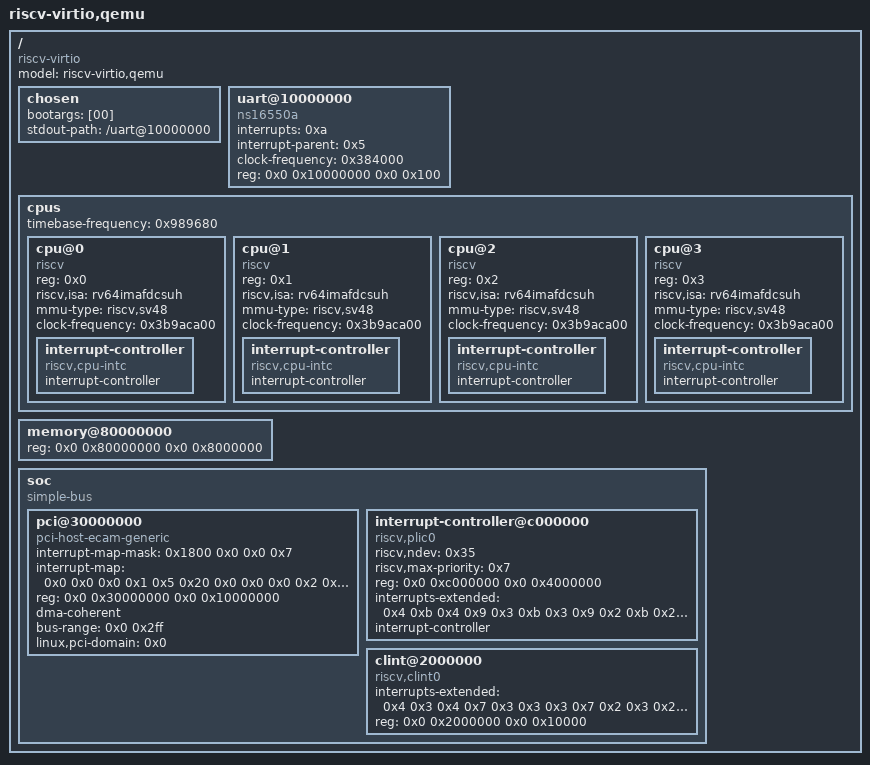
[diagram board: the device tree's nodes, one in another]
/dts-v1/;

/ {
	#address-cells = <0x2>;
	#size-cells = <0x2>;
	compatible = "riscv-virtio";
	model = "riscv-virtio,qemu";

	chosen {
		bootargs = [00];
		stdout-path = "/uart@10000000";
	};

	uart@10000000 {
		interrupts = <0xa>;
		interrupt-parent = <0x5>;
		clock-frequency = <0x384000>;
		reg = <0x0 0x10000000 0x0 0x100>;
		compatible = "ns16550a";
	};

	cpus {
		#address-cells = <0x1>;
		#size-cells = <0x0>;
		timebase-frequency = <0x989680>;

		cpu@0 {
			device_type = "cpu";
			reg = <0x0>;
			status = "okay";
			compatible = "riscv";
			riscv,isa = "rv64imafdcsuh";
			mmu-type = "riscv,sv48";
			clock-frequency = <0x3b9aca00>;

			interrupt-controller {
				#interrupt-cells = <0x1>;
				interrupt-controller;
				compatible = "riscv,cpu-intc";
				linux,phandle = <0x4>;
				phandle = <0x4>;
			};
		};

		cpu@1 {
			device_type = "cpu";
			reg = <0x1>;
			status = "okay";
			compatible = "riscv";
			riscv,isa = "rv64imafdcsuh";
			mmu-type = "riscv,sv48";
			clock-frequency = <0x3b9aca00>;

			interrupt-controller {
				#interrupt-cells = <0x1>;
				interrupt-controller;
				compatible = "riscv,cpu-intc";
				linux,phandle = <0x3>;
				phandle = <0x3>;
			};
		};

		cpu@2 {
			device_type = "cpu";
			reg = <0x2>;
			status = "okay";
			compatible = "riscv";
			riscv,isa = "rv64imafdcsuh";
			mmu-type = "riscv,sv48";
			clock-frequency = <0x3b9aca00>;

			interrupt-controller {
				#interrupt-cells = <0x1>;
				interrupt-controller;
				compatible = "riscv,cpu-intc";
				linux,phandle = <0x2>;
				phandle = <0x2>;
			};
		};

		cpu@3 {
			device_type = "cpu";
			reg = <0x3>;
			status = "okay";
			compatible = "riscv";
			riscv,isa = "rv64imafdcsuh";
			mmu-type = "riscv,sv48";
			clock-frequency = <0x3b9aca00>;

			interrupt-controller {
				#interrupt-cells = <0x1>;
				interrupt-controller;
				compatible = "riscv,cpu-intc";
				linux,phandle = <0x1>;
				phandle = <0x1>;
			};
		};
	};

	memory@80000000 {
		device_type = "memory";
		reg = <0x0 0x80000000 0x0 0x8000000>;
	};

	soc {
		#address-cells = <0x2>;
		#size-cells = <0x2>;
		compatible = "simple-bus";
		ranges;

		pci@30000000 {
			interrupt-map-mask = <0x1800 0x0 0x0 0x7>;
			interrupt-map = <0x0 0x0 0x0 0x1 0x5 0x20 0x0 0x0 0x0 0x2 0x5 0x21 0x0 0x0 0x0 0x3 0x5 0x22 0x0 0x0 0x0 0x4 0x5 0x23 0x800 0x0 0x0 0x1 0x5 0x21 0x800 0x0 0x0 0x2 0x5 0x22 0x800 0x0 0x0 0x3 0x5 0x23 0x800 0x0 0x0 0x4 0x5 0x20 0x1000 0x0 0x0 0x1 0x5 0x22 0x1000 0x0 0x0 0x2 0x5 0x23 0x1000 0x0 0x0 0x3 0x5 0x20 0x1000 0x0 0x0 0x4 0x5 0x21 0x1800 0x0 0x0 0x1 0x5 0x23 0x1800 0x0 0x0 0x2 0x5 0x20 0x1800 0x0 0x0 0x3 0x5 0x21 0x1800 0x0 0x0 0x4 0x5 0x22>;
			ranges = <0x1000000 0x0 0x0 0x0 0x3000000 0x0 0x10000 0x2000000 0x0 0x40000000 0x0 0x40000000 0x0 0x40000000>;
			reg = <0x0 0x30000000 0x0 0x10000000>;
			dma-coherent;
			bus-range = <0x0 0x2ff>;
			linux,pci-domain = <0x0>;
			device_type = "pci";
			compatible = "pci-host-ecam-generic";
			#size-cells = <0x2>;
			#interrupt-cells = <0x1>;
			#address-cells = <0x3>;
		};

		interrupt-controller@c000000 {
			linux,phandle = <0x5>;
			phandle = <0x5>;
			riscv,ndev = <0x35>;
			riscv,max-priority = <0x7>;
			reg-names = "control";
			reg = <0x0 0xc000000 0x0 0x4000000>;
			interrupts-extended = <0x4 0xb 0x4 0x9 0x3 0xb 0x3 0x9 0x2 0xb 0x2 0x9 0x1 0xb 0x1 0x9>;
			interrupt-controller;
			compatible = "riscv,plic0";
			#interrupt-cells = <0x1>;
			#address-cells = <0x0>;
		};

		clint@2000000 {
			interrupts-extended = <0x4 0x3 0x4 0x7 0x3 0x3 0x3 0x7 0x2 0x3 0x2 0x7 0x1 0x3 0x1 0x7>;
			reg = <0x0 0x2000000 0x0 0x10000>;
			compatible = "riscv,clint0";
		};
	};
};
